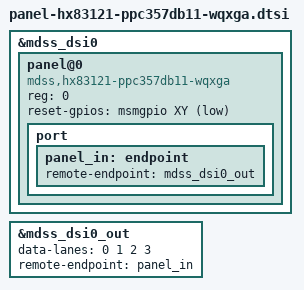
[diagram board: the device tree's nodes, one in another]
&mdss_dsi0 {
	panel@0 {
		compatible = "mdss,hx83121-ppc357db11-wqxga";
		reg = <0>;

		reset-gpios = <&msmgpio XY GPIO_ACTIVE_LOW>;

		port {
			panel_in: endpoint {
				remote-endpoint = <&mdss_dsi0_out>;
			};
		};
	};
};

&mdss_dsi0_out {
	data-lanes = <0 1 2 3>;
	remote-endpoint = <&panel_in>;
};
